# M3351 register map
File version: 1.0
Registers are 32-bit, read-write, reset 0x0 unless marked. A register's access mark holds for its fields unless they carry their own. Offsets are from the block's base; [hi:lo] are bit positions; {n}, {i} and the like mark numbered series; 'fields as' and 'values as' point back to an identical list.

## FMC — FMC Register Map
Base 0x4000C000
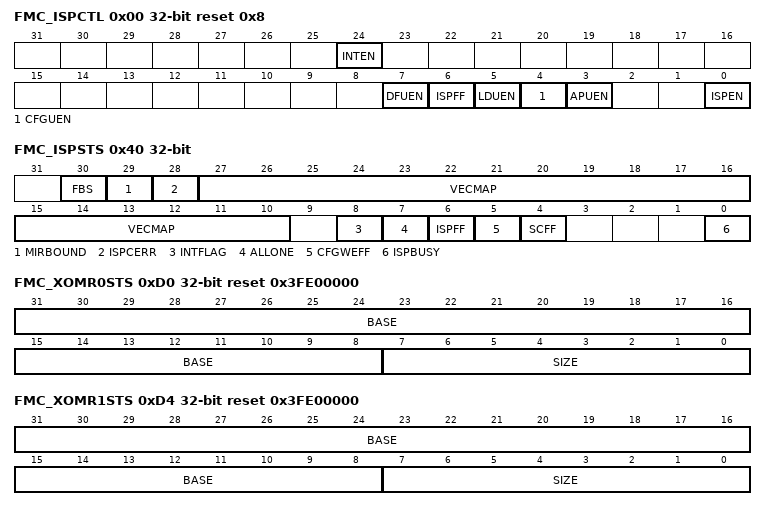
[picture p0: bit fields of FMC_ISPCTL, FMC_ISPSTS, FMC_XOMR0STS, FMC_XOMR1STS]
0x00 FMC_ISPCTL reset 0x8 — ISP Control Register
  [24] INTEN — Secure ISP INT Enable Bit (Write Protect). Note: This bit is write protected. The Write Protect is effective only when both SYS_REGLCTL at SYS_BA and SYS_BA_NS are in locked state. Before using INT, user needs to clear the INTFLAG(FMC_ISPSTS[24]) make sure INT happen at correct time.
    0=ISP INT Disabled; 1=ISP INT Enabled
  [7] DFUEN — Date Flash Update Enable Bit (Write Protect). Note: This bit is write protected. Refer to the SYS_REGLCTL register.
    0=Data Flash cannot be updated; 1=Data Flash can be updated
  [6] ISPFF — ISP Fail Flag (Write Protect). This bit is set by hardware when a triggered ISP meets any of the following conditions: This bit needs to be cleared by writing 1 to it. APROM writes to itself if APUEN is set to 0. LDROM writes to itself if LDUEN is set to 0. Data Flash writes to itself if DFUEN is set to 0. CONFIG is erased/programmed if CFGUEN is set to 0. Page Erase command at LOCK mode with ICE connection. Erase or Program command at brown-out detected. Destination address is illegal, such as over an available range. Invalid ISP commands. Read any content of bootloader with ICE connection. The address of block erase is not in APROM. ISP CMD in XOM region, except mass erase, page erase and chksum command. The wrong setting of page erase ISP CMD in XOM. Violate XOM setting one time protection. Page erase ISP CMD in Secure/Non-secure region setting page. Mass erase when MERASE (CFG0[13]) is disabled. Page erase, mass erase, 64-bit word program in OTP. ISP conflict error. Note: This bit is write protected. Refer to the SYS_REGLCTL register.
  [5] LDUEN — LDROM Update Enable Bit (Write Protect). Note: This bit is write protected. Refer to the SYS_REGLCTL register.
    0=LDROM cannot be updated; 1=LDROM can be updated
  [4] CFGUEN — CONFIG Update Enable Bit (Write Protect). Note: This bit is write protected. Refer to the SYS_REGLCTL register.
    0=CONFIG cannot be updated; 1=CONFIG can be updated
  [3] APUEN — APROM Update Enable Bit. Note: This bit is write protected. Refer to the SYS_REGLCTL register.
    0=APROM cannot be updated when the chip runs in APROM; 1=APROM can be updated when the chip runs in APROM
  [0] ISPEN — ISP Enable Bit (Write Protect). Note: This bit is write protected. The Write Protect is effective only when both SYS_REGLCTL at SYS_BA and SYS_BA_NS are in locked state.
    0=ISP function Disabled; 1=ISP function Enabled
0x04 FMC_ISPADDR — ISP Address Register
  [31:0] ISPADDR — ISP Address. This chip is equipped with embedded Flash. ISPADDR[1:0] must be kept 00 for ISP 32-bit operation. ISPADDR[2:0] must be kept 000 for ISP 64-bit operation. For CRC32 Checksum Calculation command, this field is the Flash starting address for checksum calculation, 8 Kbytes alignment is necessary for CRC32 checksum calculation.
0x08 FMC_ISPDAT — ISP Data Register
  [31:0] ISPDAT — ISP Data. Write data to this register before ISP program operation. Read data from this register after ISP read operation.
0x0C FMC_ISPCMD — ISP Command Register
  [6:0] CMD — ISP Command. The ISP command table is shown below: The other commands are invalid.
    0=FLASH Read; 4=Read Unique ID; 8=Read Flash All-One Result; 11=Read Company ID; 12=Read Device ID; 13=Read Checksum; 33=FLASH 32-bit Program; 34=FLASH Page Erase. Erase any page in two banks, except for OTP; 36=FLASH CFG word erase; 40=Run Flash All-One Verification; 44=Bank Remap; 45=Run Checksum Calculation; 46=Vector Remap; 64=FLASH 64-bit Read; 97=FLASH 64-bit Program
0x10 FMC_ISPTRG — ISP Trigger Control Register
  [0] ISPGO — ISP Start Trigger (Write Protect). Note: This bit is write protected. Refer to the SYS_REGLCTL register.
    0=ISP operation is finished; 1=ISP is progressed
0x40 FMC_ISPSTS (reset mask 0xFFFF00FF) — ISP Status Register
  [30] FBS — Flash Bank Selection (Read Only). This bit indicate which bank is selected to boot.
    0=Booting from BANK0; 1=Booting from BANK1
  [29] MIRBOUND — Mirror Boundary (Read Only)
    0=Mirror Boundary Disabled; 1=Mirror Boundary Enabled
  [28] ISPCERR — ISP Conflict Error. This bit shows when FMC is doing ISP operation, it needs to be cleared by writing 1 to FMC_ISPSTS[28]. User cannot access FMC_ISP_ADDR,FMC_ISPDAT,FMC_ISPCMD,FMC_ISPTRG. It would cause ISPFF.
  [27:10] VECMAP — Vector Page Mapping Address (Read Only). All access to 0x0000_0000~0x0000_03FF is remapped to the Flash memory address {VECMAP[17:0], 10'h000} ~ {VECMAP[17:0], 10'h3FF}
  [8] INTFLAG — ISP Interrupt Flag (Write Protect). This bit shows when FMC occurs interrupt, it needs to be cleared by writing 1 to FMC_ISPSTS[8]. Note: This function needs to be enabled by FMC_ISPCTRL[24].
    0=ISP Not Finished; 1=ISP done or ISPFF set
  [7] ALLONE — Flash All-one Verification Flag (Write Protect). This bit is set by hardware if all of Flash bits are 1, and cleared if Flash bits are not all 1 after 'Run Flash All-One Verification' is complete; this bit also can be cleared by writing 1
    0=Flash bits are not all 1 after 'Run Flash All-One Verification' complete; 1=All of Flash bits are 1 after 'Run Flash All-One Verification' complete
  [6] ISPFF — ISP Fail Flag. This bit is the mirror of ISPFF (FMC_ISPCTL[6]), it needs to be cleared by writing 1 to FMC_ISPCTL[6] or FMC_ISPSTS[6]. This bit is set by hardware when a triggered ISP meets any of the following conditions: APROM writes to itself if APUEN is set to 0. LDROM writes to itself if LDUEN is set to 0. Data Flash writes to itself if DFUEN is set to 0. CONFIG is erased/programmed if CFGUEN is set to 0. Page Erase command at LOCK mode with ICE connection. Erase or Program command at brown-out detected. Destination address is illegal, such as over an available range. Invalid ISP commands. Read any content of bootloader with ICE connection. The address of block erase is not in APROM. ISP CMD in XOM region, except mass erase, page erase and chksum command. The wrong setting of page erase ISP CMD in XOM. Violate XOM setting one time protection. Page erase ISP CMD in Secure/Non-secure region setting page. Mass erase when MERASE (CFG0[13]) is disabled. Page erase, mass erase, 64-bit word program in OTP. ISP conflict error. Note: This bit is write protected. Refer to the SYS_REGLCTL register.
  [5] CFGWEFF — Config Word Erase fail Flag(Read Only). Last time CFG word erase function after initial status. If CFGWEFF is set to 1, user needs to erase CFG region again.
    0=Success; 1=Fail
  [4] SCFF — Secure Conceal Fail Flag (Write Protect). This bit is set by hardware if any ISP command acceesses secure region when secure conceal function is enabled. This bit needs to be cleared by writing 1 to it.
    0=ISP is not accessed secure conceal region; 1=ISP is accessed secure conceal region
  [0] ISPBUSY — ISP Busy Flag (Read Only). Write 1 to start ISP operation and this bit will be cleared to 0 by hardware automatically when ISP operation is finished. This bit is the mirror of ISPGO(FMC_ISPTRG[0]).
    0=ISP operation is finished; 1=ISP is progressed
0x4C FMC_CYCCTL reset 0x1 — Flash Access Cycle Control Register
  [3:0] CYCLE — Flash Access Cycle Control (Write Protect). This register is updated by software.User needs to check the speed of HCLK and set the cycle 0. The optimized HCLK working frequency range is 126~144 MHz. Note: This bit is write protected. Refer to the SYS_REGLCTL register.
    1=CPU access with one wait cycle; Flash access cycle is 1;; 2=CPU access with two wait cycles; Flash access cycle is 2;; 3=CPU access with three wait cycles; Flash access cycle is 3;; 4=CPU access with four wait cycles; Flash access cycle is 4;; 5=CPU access with five wait cycles; Flash access cycle is 5;; 6=CPU access with six wait cycles; Flash access cycle is 6;
0x80 FMC_MPDAT0 — ISP Data0 Register
  [31:0] ISPDAT0 — ISP Data 0. Write data to this register before ISP 64-bit program operation. Read data from this register after ISP 64-bit read operation. This register is the first 32-bit data for 32-bit/64-bit programming, and it is also the mirror of FMC_ISPDAT, both registers keep the same data.
0x84 FMC_MPDAT1 — ISP Data1 Register
  [31:0] ISPDAT1 — ISP Data 1. Write data to this register before ISP 64-bit program operation. Read data from this register after ISP 64-bit read operation. This register is the second 32-bit data for 64-bit word programming.
0x90 FMC_MPDATE — ECC Error Syndrome Register
  [7:0] ISPDATE — ECC Error Syndrome. Read data from this register after ISP 64-bit read operation or ECCSEBCF(FMC_ECCSTS[0]) is high can know which bit is error. ISPDATE does not continuously store the position information of ECC errors. Therefore, if the user wants to know which bit generated the error, they need to read it before the next ISP action after an ECC single-bit error occurs, or access that position again. This register is the ECC 8-bit data.
0xD0 FMC_XOMR0STS ro reset 0x3FE00000 (reset mask 0xFFFFFF00) — XOM Region 0 Status Register
  [31:8] BASE — XOM Region 0 Base Address. BASE is the base address of XOM Region 0. Note: The base address is page aligned.
  [7:0] SIZE — XOM Region 0 Size. SIZE is the page number of XOM Region 0.
0xD4 FMC_XOMR1STS ro reset 0x3FE00000 (reset mask 0xFFFFFF00) — XOM Region 1 Status Register
  [31:8] BASE — XOM Region 1 Base Address. BASE is the base address of XOM Region 1. Note: The base address is page aligned.
  [7:0] SIZE — XOM Region 1 Size. SIZE is the page number of XOM Region 1.
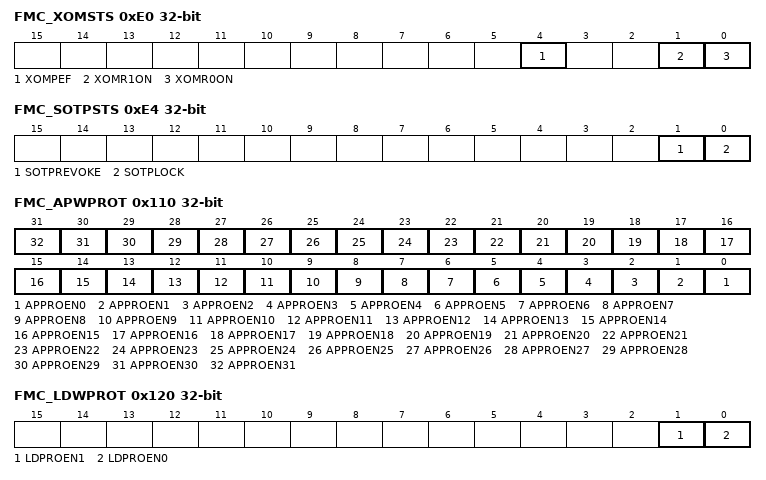
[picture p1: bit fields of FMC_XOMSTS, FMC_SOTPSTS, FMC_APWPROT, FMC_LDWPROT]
0xE0 FMC_XOMSTS ro — XOM Status Register
  [4] XOMPEF — XOM Page Erase Function Fail. XOM page erase function status. If XOMPEF is set to 1, user needs to erase XOM region again.
    0=Success; 1=Fail
  [1] XOMR1ON — XOM Region 1 On. XOM Region 1 active status.
    0=Not active; 1=XOM region 1 is active
  [0] XOMR0ON — XOM Region 0 On. XOM Region 0 active status.
    0=Not active; 1=XOM region 0 is active
0xE4 FMC_SOTPSTS ro — Secure OTP Status Register
  [1] SOTPREVOKE — Secure OTP Revoke (Read Only). The flag indicates the end of the life cycle of SOTP. All contents in SOTP would never be accessible when the SOTPREVOKE flag is set.
    0=Secure OTP is not Revoked; 1=Secure OTP is Revoked
  [0] SOTPLOCK — Secure OTP Lock (Read Only). Secure OTP Storage is for provisioning at the manufacturing stage. This flag indicates that the SOTP Storage is provisioned and immutable.
    0=Secure OTP is unlock; 1=Secure OTP is locked
0x110 FMC_APWPROT — APROM Write Protect Register
  [all] fields
    0=APROM region n is not protected; 1=APROM region n is protected
  [n] APPROEN{n} (n=0..31) — APROM Protect Enable (Write Protect). This bit indicates which APROM region is protected. Note: APROM protect region is 0x0000_0000 + n*(0x8000) to 0x0000_7fff + n*(0x8000)
0x118 FMC_APWPKEEP — APROM Write Protect Keep Register
  [15:0] APWPKEEP0 — APROM Write Protect Keep 0 (Write Protect)
    0x55AA=APWPROT register is be locked
0x11C FMC_SCACT — APROM Secure Conceal Active Register
  [0] SCACT — Secure Conceal Function Active (Write Protect). Note: secure conceal function active will base on this bit and setting of CONFIG6 is all 0.
    0=secure conceal function inactive; 1=secure conceal function active
0x120 FMC_LDWPROT — LDROM Write Protect Register
  [1] LDPROEN1 — LDROM Protect Enable (Write Protect). This bit indicates which LDROM region is protected. Note 1: LDROM protect region is 0xF10_0000 + n*(0x2000) to 0xF10_1fff + n*(0x2000). Note 2: This bit is write protected. Refer to the SYS_REGLCTL register.
    0=LDROM region n is not protected; 1=LDROM region n is protected
  [0] LDPROEN0 — LDROM Protect Enable (Write Protect). This bit indicates which LDROM region is protected. Note 1: LDROM protect region is 0xF10_0000 + n*(0x2000) to 0xF10_1fff + n*(0x2000). Note 2: This bit is write protected. Refer to the SYS_REGLCTL register.
    values as LDPROEN1
0x124 FMC_LDWPKEEP — LDROM Write Protect Keep Register
  [15:0] LDWPKEEP — LDROM Write Protect Keep (Write Protect). Note: These bits are write protected. Refer to the SYS_REGLCTL register.
    0x55AA=LDWPROT and LDWPKEEP register are locked
0x128 FMC_DFWPROT — Data Flash Write Protect Register
  [0] DFPROENn — Data Flash Protect Enable (Write Protect). This bit indicates which Data Flash region is protected. Note 1: Data Flash protect region is 0xF20_0000 + n*(0x2000) to 0xF20_1FFF + n*(0x2000). Note 2: This bit is write protected. Refer to the SYS_REGLCTL register.
    0=Data Flash region n is not protected; 1=Data Flash region n is protected
0x12C FMC_DFWPKEEP — Data Flash Write Protect Keep Register
  [15:0] DFWPKEEP — Date Flash Write Protect Keep (Write Protect). Note: These bits are write protected. Refer to the SYS_REGLCTL register.
    0x55AA=DFWPROT and DFWPKEEP register are locked
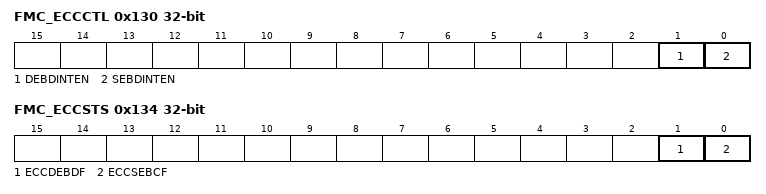
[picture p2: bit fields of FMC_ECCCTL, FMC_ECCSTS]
0x130 FMC_ECCCTL — Error Code Correction Control
  [1] DEBDINTEN — Double Error Bits Detection Interrupt Enable (Write Protect). Note: This bit is write protected. Refer to the SYS_REGLCTL register.
    0=Double Error Bits Detection Interrupt Disabled; 1=Double Error Bits Detection Interrupt Enabled
  [0] SEBDINTEN — Single Error Bits Detection Interrupt Enable (Write Protect). Note: This bit is write protected. Refer to the SYS_REGLCTL register.
    0=Single Error Bit Detection Interrupt Disabled; 1=Single Error Bit Detection Interrupt Enabled
0x134 FMC_ECCSTS — Error Code Correction status
  [1] ECCDEBDF — ECC Double Error Bits Detection Flag
    0=FMC does not detect ECC double error bits fault; 1=FMC detects ECC double error bits fault
  [0] ECCSEBCF — ECC Single Error Bits Correction Flag
    0=FMC does not detect ECC single error bits fault; 1=FMC detects and corrects ECC single error bits fault
0x138 FMC_ECCSEFAR ro — ECC Single Error Fault Address Register
  [31:0] ECCSEFAR — ECC Single Error Fault Address Register (Read Only). When FMC detects a ECCSEBCF(FMC_ECCSTS[0]) would record fault address at the register. The register is cleared by writing 1 to ECCSEBCF. ECCSEFAR is 64-bit alignment so ECCSEFAR[2:0] are always 0.
0x13C FMC_ECCDEFAR ro — ECC Double Error Fault Address Register
  [31:0] ECCDEFAR — ECC Double Error Fault Address Register (Read Only). When FMC detects a ECCDEBDF(FMC_ECCSTS[1]) would record fault address at the register. The register is cleared by writing 1 to ECCDEBDF. ECCDEBDF is 64-bit alignment so ECCDEFAR[2:0] are always 0.
